# moonlight_application register map
Vendor: Nordic Semiconductor; Series: lumos; File version: 1
CPU: CM33 r0p4, little endian, MPU, FPU, 3 interrupt priority bits, 176 interrupts, 4 SAU regions
Registers are 32-bit, read-write, reset 0x0 unless marked. A register's access mark holds for its fields unless they carry their own. Offsets are from the block's base; [hi:lo] are bit positions; {n}, {i} and the like mark numbered series; 'fields as' and 'values as' point back to an identical list.

## GLOBAL_TAD_NS — Trace and debug control 0
Base 0x40053000
Same registers: GLOBAL_TAD_S 0x50053000
0x400 SYSPWRUPREQ — System power-up request
  [0] ACTIVE — Activate power-up request
    0=NotActive (Power-up request not active); 1=Active (Power-up request active)
0x404 DBGPWRUPREQ — Debug power-up request
  fields as SYSPWRUPREQ
0x40C PDREQCLR — Clear the power request for SWD detection logic
  [0] PDREQCLR wo — Clear any false debugger connect status to allow system to use ELV voltage in System OFF
    1=Trigger operation
0x500 ENABLE — Enable debug domain and aquire selected GPIOs
  [0] ENABLE
    0=DISABLED (Disable debug domain and release selected GPIOs); 1=ENABLED (Enable debug domain and aquire selected GPIOs)
0x518 TRACEPORTSPEED — Clocking options for the Trace port debug interface Reset behavior is the same as debug components
  [1:0] TRACEPORTSPEED — Speed of Trace port clock. The TRACECLK pin output will be divided again by two from the Trace port clock.
    0=128MHz; 1=96MHz; 2=48MHz; 3=4MHz
0x520 TINSTANCE — SW-DP Target instance
  [3:0] TINSTANCE — TINSTANCE bits are used in the SW-DP DLPIDR.TINSTANCE field.

## GLOBAL_SREGS00_NS — Spare registers 0
Base 0x40056000
Same registers: GLOBAL_SREGS10_NS 0x4008C000, GLOBAL_SREGS20_NS 0x400E6000, GLOBAL_SREGS30_NS 0x4010F000, GLOBAL_SREGS00_S 0x50056000, GLOBAL_SREGS10_S 0x5008C000, GLOBAL_SREGS20_S 0x500E6000, GLOBAL_SREGS30_S 0x5010F000
{0x500+4i} REG[{i}] (i=0..1) — Description collection: Spare register n
  [31:0] VALUE
{0x600+4i} MAINREG[{i}] (i=0..0) — Description collection: Spare register n in PD_MAIN
  [7:0] VALUE
{0x700+4i} AOREG[{i}] (i=0..0) — Description collection: Spare register n in PD_AO
  [3:0] VALUE

## GLOBAL_PCGCS00_S — PCGCSlave 0
Base 0x5005E000
Same registers: GLOBAL_PCGCS30_S 0x5011E000
{0xC00+4i} PENALTY[{i}] (i=0..1) — Description collection: Penalty level for power/clock pair n
  [7:0] PENALTY — Penalty level
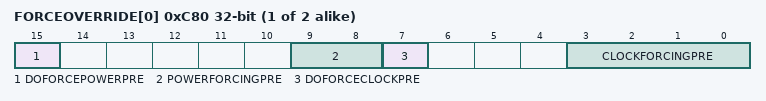
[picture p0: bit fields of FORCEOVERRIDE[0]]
{0xC80+4i} FORCEOVERRIDE[{i}] (i=0..1) — Description collection: Force override of power/clock pair n
  [15] DOFORCEPOWERPRE, [9:8] POWERFORCINGPRE, [7] DOFORCECLOCKPRE, [3:0] CLOCKFORCINGPRE

## GLOBAL_EGU10_NS — Event generator unit 0
Base 0x40087000
Same registers: GLOBAL_EGU20_NS 0x400C9000, GLOBAL_EGU10_S 0x50087000, GLOBAL_EGU20_S 0x500C9000
{0x0+4i} TASKS_TRIGGER[{i}] (i=0..15) wo — Description collection: Trigger n for triggering the corresponding TRIGGERED[n] event
  [0] TASKS_TRIGGER — Trigger n for triggering the corresponding TRIGGERED[n] event
    1=Trigger task
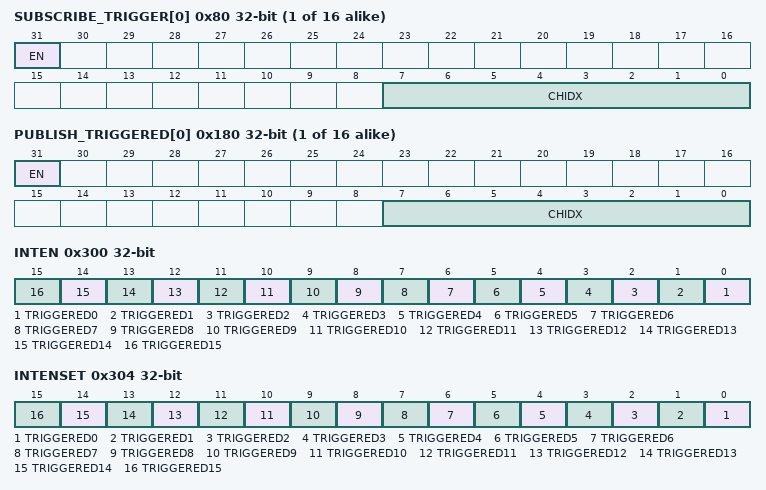
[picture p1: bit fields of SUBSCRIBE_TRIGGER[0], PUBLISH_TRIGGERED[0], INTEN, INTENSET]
{0x80+4i} SUBSCRIBE_TRIGGER[{i}] (i=0..15) — Description collection: Subscribe configuration for task TRIGGER[n]
  [31] EN
    0=Disabled (Disable subscription); 1=Enabled (Enable subscription)
  [7:0] CHIDX — DPPI channel that task TRIGGER[n] will subscribe to
{0x100+4i} EVENTS_TRIGGERED[{i}] (i=0..15) — Description collection: Event number n generated by triggering the corresponding TRIGGER[n] task
  [0] EVENTS_TRIGGERED — Event number n generated by triggering the corresponding TRIGGER[n] task
    0=NotGenerated (Event not generated); 1=Generated (Event generated)
{0x180+4i} PUBLISH_TRIGGERED[{i}] (i=0..15) — Description collection: Publish configuration for event TRIGGERED[n]
  [31] EN
    0=Disabled (Disable publishing); 1=Enabled (Enable publishing)
  [7:0] CHIDX — DPPI channel that event TRIGGERED[n] will publish to
0x300 INTEN — Enable or disable interrupt
  [all] fields
    0=Disabled; 1=Enabled
  [n] TRIGGERED{n} (n=0..15) — Enable or disable interrupt for event TRIGGERED[{n}]
0x304 INTENSET — Enable interrupt
  [all] fields
    on read: 0=Disabled (Read: Disabled); 1=Enabled (Read: Enabled) | on write: 1=Set (Enable)
  [n] TRIGGERED{n} (n=0..15) — Write '1' to enable interrupt for event TRIGGERED[{n}]
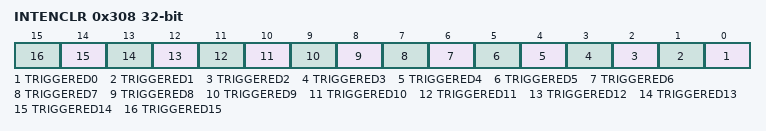
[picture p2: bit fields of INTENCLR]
0x308 INTENCLR — Disable interrupt
  [all] fields
    on read: 0=Disabled (Read: Disabled); 1=Enabled (Read: Enabled) | on write: 1=Clear (Disable)
  [n] TRIGGERED{n} (n=0..15) — Write '1' to disable interrupt for event TRIGGERED[{n}]
